VERSION ""

NS_ :

BS_:

BU_:

BO_ 800 BRAC: 1 Vector__XXX
	SG_ b_StartTest : 0|1@0+ (0,0) [0|0] "" Vector__XXX

BO_ 799 DLFR: 8 Vector__XXX
	SG_ DF_Breath : 0|32@0+ (0.0009766,0) [0|0] "" Vector__XXX

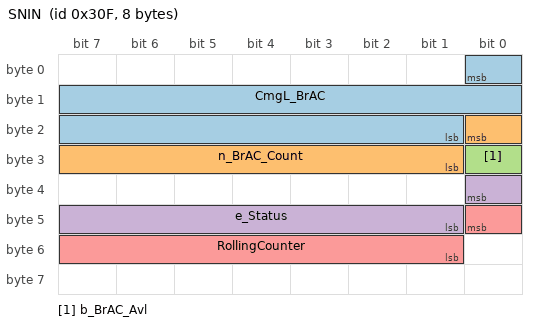
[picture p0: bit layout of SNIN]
BO_ 783 SNIN: 8 Vector__XXX
	SG_ CmgL_BrAC : 0|16@0+ (0.00012207,0) [0|0] "mg/L" Vector__XXX
	SG_ n_BrAC_Count : 16|8@0+ (0,0) [0|0] "" Vector__XXX
	SG_ b_BrAC_Avl : 24|1@0+ (0,0) [0|0] "" Vector__XXX
	SG_ e_Status : 32|8@0+ (0,0) [0|0] "" Vector__XXX
	SG_ RollingCounter : 40|8@0+ (0,0) [0|0] "" Vector__XXX

CM_ BO_ 783 "Breath Alcohol and Sensor Status";
CM_ BO_ 799 "Sample Dilution Factor";
CM_ SG_ 799 DF_Breath "Breath sample dilution factor";
CM_ BO_ 800 "Sensor Input Control";
CM_ SG_ 800 b_StartTest "Start test flag";
BA_DEF_ BO_  "VFrameFormat" ENUM  "StandardCAN","ExtendedCAN","reserved","J1939PG";
BA_DEF_  "DatabaseVersion" STRING ;
BA_DEF_  "BusType" STRING ;
BA_DEF_  "ProtocolType" STRING ;
BA_DEF_  "DatabaseCompiler" STRING ;
BA_DEF_DEF_  "VFrameFormat" "StandardCAN";
BA_DEF_DEF_  "DatabaseVersion" "DEMO PLUS";
BA_DEF_DEF_  "BusType" "";
BA_DEF_DEF_  "ProtocolType" "";
BA_DEF_DEF_  "DatabaseCompiler" "";
BA_ "ProtocolType" "J1939";
BA_ "BusType" "CAN";
BA_ "DatabaseCompiler" "CSS ELECTRONICS (WWW.CSSELECTRONICS.COM)";
BA_ "DatabaseVersion" "1.0.0";
